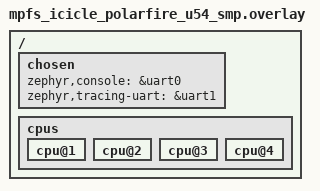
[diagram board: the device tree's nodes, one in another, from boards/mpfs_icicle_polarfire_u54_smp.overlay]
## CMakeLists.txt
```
# Copyright (c) 2025 Analog Devices, Inc.
# Copyright (c) 2025 Antmicro <www.antmicro.com>
#
# SPDX-License-Identifier: Apache-2.0

cmake_minimum_required(VERSION 3.20.0)

include(${CMAKE_CURRENT_LIST_DIR}/../../common/boards.cmake)

find_package(Zephyr REQUIRED HINTS $ENV{ZEPHYR_BASE})
project(app)
target_sources(app PRIVATE ./src/main.c)
```

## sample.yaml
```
# Copyright (c) 2025 Analog Devices, Inc.
# Copyright (c) 2025 Antmicro <www.antmicro.com>
#
# SPDX-License-Identifier: Apache-2.0

sample:
  name: smp
common:
  tags: profiling
  platform_allow:
    - mpfs_icicle/polarfire/u54/smp
tests:
  sample.trace.smp.ctf.robot:
    harness: robot
    harness_config:
      robot_testsuite: smp_ctf.robot
```

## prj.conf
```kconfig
CONFIG_ZPL=y
CONFIG_ZPL_TRACE=y
CONFIG_ZPL_TRACE_FULL_MODE=y
CONFIG_ZPL_TRACE_FORMAT_CTF=y

CONFIG_SYS_HEAP_ARRAY_SIZE=4
CONFIG_HEAP_MEM_POOL_SIZE=256
CONFIG_COMMON_LIBC_MALLOC=y
CONFIG_ZPL_MEMORY_PROFILING=y
CONFIG_ZPL_MEMORY_PROFILING_INTERVAL=100
CONFIG_ZPL_MEMORY_PROFILING_THREAD_PRIORITY=-1

CONFIG_CPU_LOAD=y
CONFIG_ZPL_CPU_LOAD_TRACE=y
CONFIG_ZPL_CPU_LOAD_PROFILING=y
CONFIG_ZPL_CPU_LOAD_PROFILING_INTERVAL=100
CONFIG_ZPL_CPU_LOAD_PROFILING_THREAD_PRIORITY=-1
CONFIG_ZPL_CPU_LOAD_PROFILING_THREAD_DELAY=1000

CONFIG_TRACING_SYNC=y
CONFIG_MAIN_STACK_SIZE=8192

CONFIG_SMP=y
CONFIG_TEST=y
CONFIG_THREAD_NAME=y
CONFIG_SCHED_CPU_MASK=y

CONFIG_IDLE_STACK_SIZE=1024
```

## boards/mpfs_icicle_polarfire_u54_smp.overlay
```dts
/ {
	chosen {
		zephyr,console = &uart0;
		zephyr,tracing-uart = &uart1;
	};

	cpus {
		cpu@1 {
			status = "okay";
		};
		cpu@2 {
			status = "okay";
		};
		cpu@3 {
			status = "okay";
		};
		cpu@4 {
			status = "okay";
		};
	};
};
```

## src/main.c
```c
/*
 * Copyright (c) 2025 Analog Devices, Inc.
 * Copyright (c) 2025 Antmicro <www.antmicro.com>
 *
 * SPDX-License-Identifier: Apache-2.0
 */

#include <zephyr/kernel.h>

#include <zpl.h>

/* size of stack area used by each thread */
#define STACK_SIZE 1024

/* number of threads to run */
#define THREADS_NUM 4

static K_THREAD_STACK_ARRAY_DEFINE(tstack, THREADS_NUM, STACK_SIZE);
static struct k_thread tthread[THREADS_NUM];
static struct k_sem tsem[THREADS_NUM];

void thread_loop(void *my_sem_, void *other_sem_, void *arg3)
{
	struct k_sem *my_sem = (struct k_sem *)my_sem_;
	struct k_sem *other_sem = (struct k_sem *)other_sem_;
	char my_name[20];

	snprintf(my_name, sizeof(my_name), "%s", k_thread_name_get(k_current_get()));

	while (true) {
		/* take my semaphore */
		k_sem_take(my_sem, K_FOREVER);

		printk("%s: running on cpu %d\n", my_name, arch_curr_cpu()->id);
		sys_trace_named_event(my_name, arch_curr_cpu()->id, 0);

		/* wait a while, then let other thread have a turn */
		k_busy_wait(50);
		k_msleep(10);

		k_sem_give(other_sem);
	}
}

int main(void)
{
	/* initialize semaphores */
	for (int i = 0; i < THREADS_NUM; ++i) {
		k_sem_init(&tsem[i], i == 0 ? 1 : 0, 1);
	}

	/* create and start threads */
	for (int i = 0; i < THREADS_NUM; ++i) {
		char thread_name[32];
		snprintf(thread_name, sizeof(thread_name), "thread_%c", 'a' + i);
		k_thread_create(&tthread[i], tstack[i], STACK_SIZE, thread_loop, (void *)&tsem[i],
				(void *)&tsem[(i + 1) % THREADS_NUM], NULL, 7, 0, K_FOREVER);
		k_thread_name_set(&tthread[i], thread_name);
		k_thread_cpu_pin(&tthread[i], i % arch_num_cpus());
		k_thread_start(&tthread[i]);
	}

	return 0;
}
```
